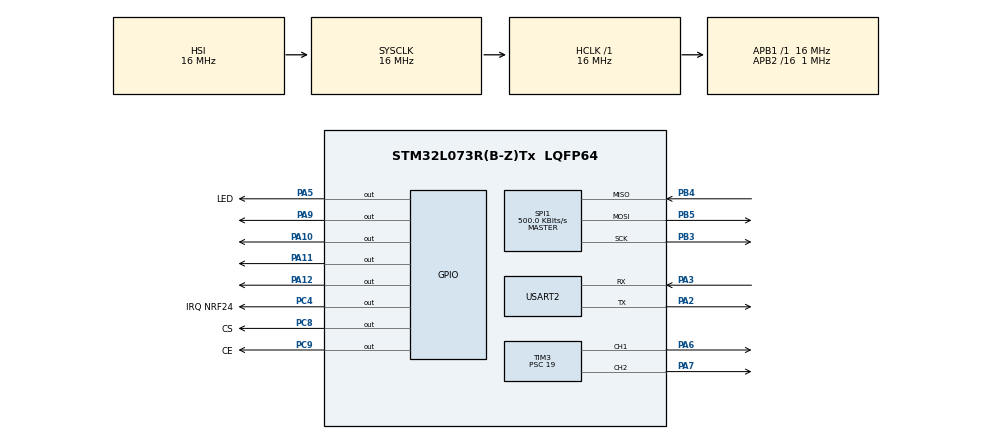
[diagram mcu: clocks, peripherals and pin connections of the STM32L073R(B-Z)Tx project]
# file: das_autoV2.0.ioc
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IWDG.Prescaler=IWDG_PRESCALER_64
Mcu.Family=STM32L0
Mcu.Name=STM32L073R(B-Z)Tx
Mcu.Package=LQFP64
PA10.Signal=GPIO_Output
PA11.Signal=GPIO_Output
PA12.Signal=GPIO_Output
PA2.Mode=Asynchronous
PA2.Signal=USART2_TX
PA3.Mode=Asynchronous
PA3.Signal=USART2_RX
PA5.GPIO_Label=LED
PA5.Signal=GPIO_Output
PA6.Signal=S_TIM3_CH1
PA7.Signal=S_TIM3_CH2
PA9.Signal=GPIO_Output
PB3.Mode=Full_Duplex_Master
PB3.Signal=SPI1_SCK
PB4.Mode=Full_Duplex_Master
PB4.Signal=SPI1_MISO
PB5.Mode=Full_Duplex_Master
PB5.Signal=SPI1_MOSI
PC4.GPIO_Label=IRQ NRF24
PC4.Signal=GPIO_Output
PC8.GPIO_Label=CS
PC8.Signal=GPIO_Output
PC9.GPIO_Label=CE
PC9.Signal=GPIO_Output
ProjectManager.HeapSize=0x200
ProjectManager.StackSize=0x400
ProjectManager.TargetToolchain=SW4STM32
RCC.AHBFreq_Value=16000000
RCC.APB1Freq_Value=16000000
RCC.APB1TimFreq_Value=16000000
RCC.APB2CLKDivider=RCC_HCLK_DIV16
RCC.APB2Freq_Value=1000000
RCC.APB2TimFreq_Value=2000000
RCC.HCLKFreq_Value=16000000
RCC.HSE_VALUE=8000000
RCC.HSI16_VALUE=16000000
RCC.HSI48_VALUE=48000000
RCC.HSI_VALUE=16000000
RCC.LSEState=RCC_LSE_ON
RCC.LSE_VALUE=32768
RCC.MSI_VALUE=2097000
RCC.SYSCLKFreq_VALUE=16000000
RCC.SYSCLKSource=RCC_SYSCLKSOURCE_HSI
RCC.VCOOutputFreq_Value=48000000
SH.S_TIM3_CH1.0=TIM3_CH1,PWM Generation1 CH1
SH.S_TIM3_CH2.0=TIM3_CH2,PWM Generation2 CH2
SPI1.CalculateBaudRate=500.0 KBits/s
SPI1.Direction=SPI_DIRECTION_2LINES
SPI1.Mode=SPI_MODE_MASTER
SPI1.VirtualType=VM_MASTER
TIM3.Channel-PWM\ Generation1\ CH1=TIM_CHANNEL_1
TIM3.Channel-PWM\ Generation2\ CH2=TIM_CHANNEL_2
TIM3.Period=1000
TIM3.Prescaler=19
TIM3.Pulse-PWM\ Generation1\ CH1=500
TIM3.Pulse-PWM\ Generation2\ CH2=500
USART2.VirtualMode-Asynchronous=VM_ASYNC
VP_IWDG_VS_IWDG.Mode=IWDG_Activate
VP_TIM3_VS_ClockSourceINT.Mode=Internal
board=NUCLEO-L073RZ

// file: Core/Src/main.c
/* USER CODE BEGIN Header */
/**
  ******************************************************************************
  * @file           : main.c
  * @brief          : Main program body
  ******************************************************************************
  * @attention
  *
  * <h2><center>&copy; Copyright (c) 2021 STMicroelectronics.
  * All rights reserved.</center></h2>
  *
  * This software component is licensed by ST under BSD 3-Clause license,
  * the "License"; You may not use this file except in compliance with the
  * License. You may obtain a copy of the License at:
  *                        opensource.org/licenses/BSD-3-Clause
  *
  ******************************************************************************
  */
/* USER CODE END Header */
#include "main.h"

/* USER CODE BEGIN Includes */
#include "Boot.h"
/* USER CODE END Includes */

IWDG_HandleTypeDef hiwdg;

SPI_HandleTypeDef hspi1;

TIM_HandleTypeDef htim3;

UART_HandleTypeDef huart2;

void SystemClock_Config(void);
static void MX_GPIO_Init(void);
static void MX_IWDG_Init(void);
static void MX_SPI1_Init(void);
static void MX_TIM3_Init(void);
static void MX_USART2_UART_Init(void);

int main(void)
{

  /* MCU Configuration--------------------------------------------------------*/

  /* Reset of all peripherals, Initializes the Flash interface and the Systick. */
  HAL_Init();

  /* Configure the system clock */
  SystemClock_Config();

  /* Initialize all configured peripherals */
  MX_GPIO_Init();
  MX_IWDG_Init();
  MX_SPI1_Init();
  MX_TIM3_Init();
  MX_USART2_UART_Init();
  /* USER CODE BEGIN 2 */
  Boot();
  /* USER CODE END 2 */

  /* Infinite loop */
  while (1)
  {

  }
}

void SystemClock_Config(void)
{
  RCC_OscInitTypeDef RCC_OscInitStruct = {0};
  RCC_ClkInitTypeDef RCC_ClkInitStruct = {0};
  RCC_PeriphCLKInitTypeDef PeriphClkInit = {0};

  /** Configure the main internal regulator output voltage
  */
  __HAL_PWR_VOLTAGESCALING_CONFIG(PWR_REGULATOR_VOLTAGE_SCALE1);
  /** Initializes the RCC Oscillators according to the specified parameters
  * in the RCC_OscInitTypeDef structure.
  */
  RCC_OscInitStruct.OscillatorType = RCC_OSCILLATORTYPE_HSI|RCC_OSCILLATORTYPE_LSI;
  RCC_OscInitStruct.HSIState = RCC_HSI_ON;
  RCC_OscInitStruct.HSICalibrationValue = RCC_HSICALIBRATION_DEFAULT;
  RCC_OscInitStruct.LSIState = RCC_LSI_ON;
  RCC_OscInitStruct.PLL.PLLState = RCC_PLL_NONE;
  if (HAL_RCC_OscConfig(&RCC_OscInitStruct) != HAL_OK)
  {
    Error_Handler();
  }
  /** Initializes the CPU, AHB and APB buses clocks
  */
  RCC_ClkInitStruct.ClockType = RCC_CLOCKTYPE_HCLK|RCC_CLOCKTYPE_SYSCLK
                              |RCC_CLOCKTYPE_PCLK1|RCC_CLOCKTYPE_PCLK2;
  RCC_ClkInitStruct.SYSCLKSource = RCC_SYSCLKSOURCE_HSI;
  RCC_ClkInitStruct.AHBCLKDivider = RCC_SYSCLK_DIV1;
  RCC_ClkInitStruct.APB1CLKDivider = RCC_HCLK_DIV1;
  RCC_ClkInitStruct.APB2CLKDivider = RCC_HCLK_DIV16;

  if (HAL_RCC_ClockConfig(&RCC_ClkInitStruct, FLASH_LATENCY_0) != HAL_OK)
  {
    Error_Handler();
  }
  PeriphClkInit.PeriphClockSelection = RCC_PERIPHCLK_USART2;
  PeriphClkInit.Usart2ClockSelection = RCC_USART2CLKSOURCE_PCLK1;
  if (HAL_RCCEx_PeriphCLKConfig(&PeriphClkInit) != HAL_OK)
  {
    Error_Handler();
  }
}

static void MX_IWDG_Init(void)
{

  hiwdg.Instance = IWDG;
  hiwdg.Init.Prescaler = IWDG_PRESCALER_64;
  hiwdg.Init.Window = 4095;
  hiwdg.Init.Reload = 4095;
  if (HAL_IWDG_Init(&hiwdg) != HAL_OK)
  {
    Error_Handler();
  }

}

static void MX_SPI1_Init(void)
{

  /* SPI1 parameter configuration*/
  hspi1.Instance = SPI1;
  hspi1.Init.Mode = SPI_MODE_MASTER;
  hspi1.Init.Direction = SPI_DIRECTION_2LINES;
  hspi1.Init.DataSize = SPI_DATASIZE_8BIT;
  hspi1.Init.CLKPolarity = SPI_POLARITY_LOW;
  hspi1.Init.CLKPhase = SPI_PHASE_1EDGE;
  hspi1.Init.NSS = SPI_NSS_SOFT;
  hspi1.Init.BaudRatePrescaler = SPI_BAUDRATEPRESCALER_2;
  hspi1.Init.FirstBit = SPI_FIRSTBIT_MSB;
  hspi1.Init.TIMode = SPI_TIMODE_DISABLE;
  hspi1.Init.CRCCalculation = SPI_CRCCALCULATION_DISABLE;
  hspi1.Init.CRCPolynomial = 7;
  if (HAL_SPI_Init(&hspi1) != HAL_OK)
  {
    Error_Handler();
  }

}

static void MX_TIM3_Init(void)
{

  TIM_ClockConfigTypeDef sClockSourceConfig = {0};
  TIM_MasterConfigTypeDef sMasterConfig = {0};
  TIM_OC_InitTypeDef sConfigOC = {0};

  htim3.Instance = TIM3;
  htim3.Init.Prescaler = 19;
  htim3.Init.CounterMode = TIM_COUNTERMODE_UP;
  htim3.Init.Period = 1000;
  htim3.Init.ClockDivision = TIM_CLOCKDIVISION_DIV1;
  htim3.Init.AutoReloadPreload = TIM_AUTORELOAD_PRELOAD_DISABLE;
  if (HAL_TIM_Base_Init(&htim3) != HAL_OK)
  {
    Error_Handler();
  }
  sClockSourceConfig.ClockSource = TIM_CLOCKSOURCE_INTERNAL;
  if (HAL_TIM_ConfigClockSource(&htim3, &sClockSourceConfig) != HAL_OK)
  {
    Error_Handler();
  }
  if (HAL_TIM_PWM_Init(&htim3) != HAL_OK)
  {
    Error_Handler();
  }
  sMasterConfig.MasterOutputTrigger = TIM_TRGO_RESET;
  sMasterConfig.MasterSlaveMode = TIM_MASTERSLAVEMODE_DISABLE;
  if (HAL_TIMEx_MasterConfigSynchronization(&htim3, &sMasterConfig) != HAL_OK)
  {
    Error_Handler();
  }
  sConfigOC.OCMode = TIM_OCMODE_PWM1;
  sConfigOC.Pulse = 500;
  sConfigOC.OCPolarity = TIM_OCPOLARITY_HIGH;
  sConfigOC.OCFastMode = TIM_OCFAST_DISABLE;
  if (HAL_TIM_PWM_ConfigChannel(&htim3, &sConfigOC, TIM_CHANNEL_1) != HAL_OK)
  {
    Error_Handler();
  }
  if (HAL_TIMEx_RemapConfig(&htim3, TIM3_TI1_GPIO) != HAL_OK)
  {
    Error_Handler();
  }
  if (HAL_TIM_PWM_ConfigChannel(&htim3, &sConfigOC, TIM_CHANNEL_2) != HAL_OK)
  {
    Error_Handler();
  }
  HAL_TIM_MspPostInit(&htim3);

}

static void MX_USART2_UART_Init(void)
{

  huart2.Instance = USART2;
  huart2.Init.BaudRate = 115200;
  huart2.Init.WordLength = UART_WORDLENGTH_8B;
  huart2.Init.StopBits = UART_STOPBITS_1;
  huart2.Init.Parity = UART_PARITY_NONE;
  huart2.Init.Mode = UART_MODE_TX_RX;
  huart2.Init.HwFlowCtl = UART_HWCONTROL_NONE;
  huart2.Init.OverSampling = UART_OVERSAMPLING_16;
  huart2.Init.OneBitSampling = UART_ONE_BIT_SAMPLE_DISABLE;
  huart2.AdvancedInit.AdvFeatureInit = UART_ADVFEATURE_NO_INIT;
  if (HAL_UART_Init(&huart2) != HAL_OK)
  {
    Error_Handler();
  }

}

static void MX_GPIO_Init(void)
{
  GPIO_InitTypeDef GPIO_InitStruct = {0};

  /* GPIO Ports Clock Enable */
  __HAL_RCC_GPIOA_CLK_ENABLE();
  __HAL_RCC_GPIOC_CLK_ENABLE();
  __HAL_RCC_GPIOB_CLK_ENABLE();

  /*Configure GPIO pin Output Level */
  HAL_GPIO_WritePin(GPIOA, LED_Pin|GPIO_PIN_9|GPIO_PIN_10|GPIO_PIN_11
                          |GPIO_PIN_12, GPIO_PIN_RESET);

  /*Configure GPIO pin Output Level */
  HAL_GPIO_WritePin(GPIOC, IRQ_NRF24_Pin|CS_Pin|CE_Pin, GPIO_PIN_RESET);

  /*Configure GPIO pins : LED_Pin PA9 PA10 PA11
                           PA12 */
  GPIO_InitStruct.Pin = LED_Pin|GPIO_PIN_9|GPIO_PIN_10|GPIO_PIN_11
                          |GPIO_PIN_12;
  GPIO_InitStruct.Mode = GPIO_MODE_OUTPUT_PP;
  GPIO_InitStruct.Pull = GPIO_NOPULL;
  GPIO_InitStruct.Speed = GPIO_SPEED_FREQ_LOW;
  HAL_GPIO_Init(GPIOA, &GPIO_InitStruct);

  /*Configure GPIO pins : IRQ_NRF24_Pin CS_Pin CE_Pin */
  GPIO_InitStruct.Pin = IRQ_NRF24_Pin|CS_Pin|CE_Pin;
  GPIO_InitStruct.Mode = GPIO_MODE_OUTPUT_PP;
  GPIO_InitStruct.Pull = GPIO_NOPULL;
  GPIO_InitStruct.Speed = GPIO_SPEED_FREQ_LOW;
  HAL_GPIO_Init(GPIOC, &GPIO_InitStruct);

}

void Error_Handler(void)
{
  __disable_irq();
  while (1)
  {
  }
}

/************************ (C) COPYRIGHT STMicroelectronics *****END OF FILE****/
